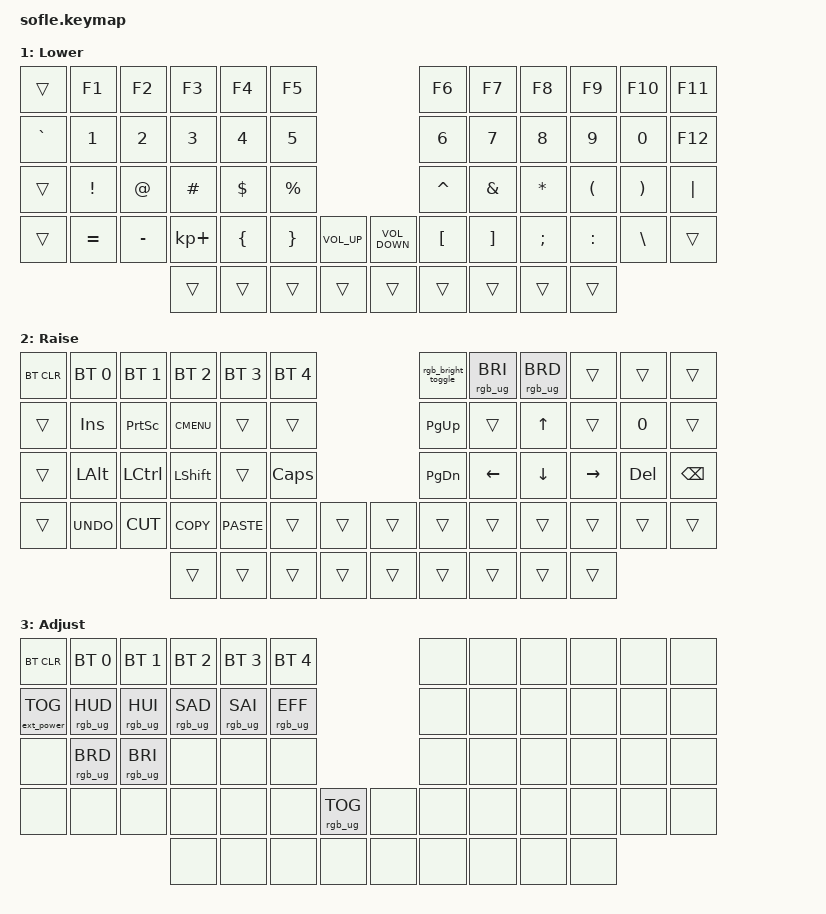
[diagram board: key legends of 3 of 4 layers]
/*
 * Copyright (c) 2020 The ZMK Contributors
 *
 * SPDX-License-Identifier: MIT
 */

#include <behaviors.dtsi>
#include <dt-bindings/zmk/bt.h>
#include <dt-bindings/zmk/ext_power.h>
#include <dt-bindings/zmk/keys.h>
#include <dt-bindings/zmk/outputs.h>
#include <dt-bindings/zmk/rgb.h>

// LED strip configuration for RGB
&led_strip {
    chain-length = <35>;
};

// Left encoder configuration
&left_encoder {
    resolution = <2>;
};

/ {
    // Activate ADJUST layer by pressing raise and lower
    conditional_layers {
        compatible = "zmk,conditional-layers";
        adjust_layer {
            if-layers = <1 2>;
            then-layer = <3>;
        };
    };

    macros {
        rgb_brightness_off: rgb_brightness_off {
            compatible = "zmk,behavior-macro";
            #binding-cells = <0>;
            bindings = <&rgb_ug RGB_BRD &rgb_ug RGB_BRD &rgb_ug RGB_BRD &rgb_ug RGB_BRD &rgb_ug RGB_BRD>;
        };
        rgb_brightness_on: rgb_brightness_on {
            compatible = "zmk,behavior-macro";
            #binding-cells = <0>;
            bindings = <&rgb_ug RGB_BRI &rgb_ug RGB_BRI &rgb_ug RGB_BRI>;
        };
    };

    behaviors {
        rgb_bright_toggle: rgb_bright_toggle {
            compatible = "zmk,behavior-mod-morph";
            label = "RGB_BRIGHT_TOGGLE";
            #binding-cells = <0>;
            bindings = <&rgb_brightness_off>, <&rgb_brightness_on>;
            mods = <(MOD_LSFT|MOD_RSFT)>;
        };
    };

    keymap {
        compatible = "zmk,keymap";

        // =================================================================
        // LAYER 0: DEFAULT (QWERTY)
        // =================================================================
        default_layer {
            label = "QWERTY";
            // ┌─────┬─────┬─────┬─────┬─────┬─────┐                    ┌─────┬─────┬─────┬─────┬─────┬─────┐
            // │  `  │  1  │  2  │  3  │  4  │  5  │                    │  6  │  7  │  8  │  9  │  0  │  -  │
            // ├─────┼─────┼─────┼─────┼─────┼─────┤                    ├─────┼─────┼─────┼─────┼─────┼─────┤
            // │ ESC │  Q  │  W  │  E  │  R  │  T  │                    │  Y  │  U  │  I  │  O  │  P  │BKSPC│
            // ├─────┼─────┼─────┼─────┼─────┼─────┤                    ├─────┼─────┼─────┼─────┼─────┼─────┤
            // │ TAB │  A  │  S  │  D  │  F  │  G  │                    │  H  │  J  │  K  │  L  │  ;  │  '  │
            // ├─────┼─────┼─────┼─────┼─────┼─────┼─────┐        ┌─────┼─────┼─────┼─────┼─────┼─────┼─────┤
            // │SHIFT│  Z  │  X  │  C  │  V  │  B  │MUTE │        │     │  N  │  M  │  ,  │  .  │  /  │SHIFT│
            // └─────┴─────┴─────┼─────┼─────┼─────┼─────┤        ├─────┼─────┼─────┼─────┴─────┴─────┴─────┘
            //                   │ GUI │ ALT │CTRL │LOWER│        │RAISE│RCTRL│RALT │  \  │
            //                   │     │     │     │     │        │     │     │     │     │
            //                   └─────┴─────┴─────┼─────┤        ├─────┼─────┴─────┴─────┘
            //                                     │SPACE│        │ RET │
            //                                     └─────┘        └─────┘
            bindings = <
                &kp GRAVE  &kp N1    &kp N2    &kp N3     &kp N4     &kp N5                           &kp N6     &kp N7     &kp N8     &kp N9    &kp N0    &kp MINUS
                &kp ESC    &kp Q     &kp W     &kp E      &kp R      &kp T                            &kp Y      &kp U      &kp I      &kp O     &kp P     &kp BSPC
                &kp TAB    &kp A     &kp S     &kp D      &kp F      &kp G                            &kp H      &kp J      &kp K      &kp L     &kp SEMI  &kp SQT
                &kp LSHFT  &kp Z     &kp X     &kp C      &kp V      &kp B  &kp C_MUTE     &kp C_MUTE &kp N      &kp M      &kp COMMA  &kp DOT   &kp SLASH &kp RSHFT
                                     &kp LGUI  &kp LALT   &kp LCTRL  &mo 1  &kp SPACE      &kp RET    &mo 2      &kp RCTRL  &kp RALT   &kp BACKSLASH
            >;

            sensor-bindings = <&inc_dec_kp C_VOL_UP C_VOL_DN &inc_dec_kp PG_UP PG_DN>;
        };

        // =================================================================
        // LAYER 1: LOWER (NUMBERS, SYMBOLS, FUNCTION KEYS)
        // =================================================================
        lower_layer {
            label = "Lower";
            // ┌─────┬─────┬─────┬─────┬─────┬─────┐                    ┌─────┬─────┬─────┬─────┬─────┬─────┐
            // │     │ F1  │ F2  │ F3  │ F4  │ F5  │                    │ F6  │ F7  │ F8  │ F9  │ F10 │ F11 │
            // ├─────┼─────┼─────┼─────┼─────┼─────┤                    ├─────┼─────┼─────┼─────┼─────┼─────┤
            // │  `  │  1  │  2  │  3  │  4  │  5  │                    │  6  │  7  │  8  │  9  │  0  │ F12 │
            // ├─────┼─────┼─────┼─────┼─────┼─────┤                    ├─────┼─────┼─────┼─────┼─────┼─────┤
            // │     │  !  │  @  │  #  │  $  │  %  │                    │  ^  │  &  │  *  │  (  │  )  │  |  │
            // ├─────┼─────┼─────┼─────┼─────┼─────┼─────┐        ┌─────┼─────┼─────┼─────┼─────┼─────┼─────┤
            // │     │  =  │  -  │  +  │  {  │  }  │VOLUP│        │VOLDW│  [  │  ]  │  ;  │  :  │  \  │     │
            // └─────┴─────┴─────┼─────┼─────┼─────┼─────┤        ├─────┼─────┼─────┼─────┴─────┴─────┴─────┘
            //                   │     │     │     │     │        │     │     │     │     │
            //                   │     │     │     │     │        │     │     │     │     │
            //                   └─────┴─────┴─────┼─────┤        ├─────┼─────┴─────┴─────┘
            //                                     │     │        │     │
            //                                     └─────┘        └─────┘
            bindings = <
                &trans     &kp F1     &kp F2     &kp F3       &kp F4     &kp F5                                           &kp F6     &kp F7    &kp F8     &kp F9     &kp F10   &kp F11
                &kp GRAVE  &kp N1     &kp N2     &kp N3       &kp N4     &kp N5                                           &kp N6     &kp N7    &kp N8     &kp N9     &kp N0    &kp F12
                &trans     &kp EXCL   &kp AT     &kp HASH     &kp DLLR   &kp PRCNT                                        &kp CARET  &kp AMPS  &kp ASTRK  &kp LPAR   &kp RPAR  &kp PIPE
                &trans     &kp EQUAL  &kp MINUS  &kp KP_PLUS  &kp LBRC   &kp RBRC   &kp C_VOLUME_UP    &kp C_VOLUME_DOWN  &kp LBKT   &kp RBKT  &kp SEMI   &kp COLON  &kp BSLH  &trans
                                                 &trans       &trans     &trans     &trans             &trans  &trans     &trans     &trans    &trans
            >;

            sensor-bindings = <&inc_dec_kp C_VOL_UP C_VOL_DN &inc_dec_kp PG_UP PG_DN>;
        };

        // =================================================================
        // LAYER 2: RAISE (NAVIGATION, BLUETOOTH, SYSTEM)
        // =================================================================
        raise_layer {
            label = "Raise";
            // ┌─────┬─────┬─────┬─────┬─────┬─────┐                    ┌─────┬─────┬─────┬─────┬─────┬─────┐
            // │BTCLR│ BT1 │ BT2 │ BT3 │ BT4 │ BT5 │                    │RGB↕ │RGB+ │RGB- │     │     │     │
            // ├─────┼─────┼─────┼─────┼─────┼─────┤                    ├─────┼─────┼─────┼─────┼─────┼─────┤
            // │     │ INS │PSCR │MENU │     │     │                    │PGUP │     │  ↑  │     │  0  │     │
            // ├─────┼─────┼─────┼─────┼─────┼─────┤                    ├─────┼─────┼─────┼─────┼─────┼─────┤
            // │     │ ALT │CTRL │SHIFT│     │CAPS │                    │PGDN │  ←  │  ↓  │  →  │ DEL │BKSPC│
            // ├─────┼─────┼─────┼─────┼─────┼─────┼─────┐        ┌─────┼─────┼─────┼─────┼─────┼─────┼─────┤
            // │     │UNDO │ CUT │COPY │PASTE│     │     │        │     │     │     │     │     │     │     │
            // └─────┴─────┴─────┼─────┼─────┼─────┼─────┤        ├─────┼─────┼─────┼─────┴─────┴─────┴─────┘
            //                   │     │     │     │     │        │     │     │     │     │
            //                   │     │     │     │     │        │     │     │     │     │
            //                   └─────┴─────┴─────┼─────┤        ├─────┼─────┴─────┴─────┘
            //                                     │     │        │     │
            //                                     └─────┘        └─────┘
            bindings = <
                &bt BT_CLR  &bt BT_SEL 0  &bt BT_SEL 1  &bt BT_SEL 2  &bt BT_SEL 3  &bt BT_SEL 4                          &rgb_bright_toggle  &rgb_ug RGB_BRI  &rgb_ug RGB_BRD  &trans     &trans  &trans
                &trans      &kp INS       &kp PSCRN     &kp K_CMENU   &trans        &trans                                &kp PG_UP        &trans           &kp UP           &trans     &kp N0  &trans
                &trans      &kp LALT      &kp LCTRL     &kp LSHFT     &trans        &kp CLCK                              &kp PG_DN        &kp LEFT         &kp DOWN         &kp RIGHT  &kp DEL &kp BSPC
                &trans      &kp K_UNDO    &kp K_CUT     &kp K_COPY    &kp K_PASTE   &trans       &trans     &trans        &trans           &trans           &trans           &trans     &trans  &trans
                                                        &trans        &trans        &trans       &trans     &trans        &trans           &trans           &trans           &trans
            >;

            sensor-bindings = <&inc_dec_kp C_VOL_UP C_VOL_DN &inc_dec_kp PG_UP PG_DN>;
        };

        // =================================================================
        // LAYER 3: ADJUST (RGB CONTROLS, ADVANCED BLUETOOTH, SYSTEM)
        // =================================================================
        adjust_layer {
            label = "Adjust";
            // ┌─────┬─────┬─────┬─────┬─────┬─────┐                    ┌─────┬─────┬─────┬─────┬─────┬─────┐
            // │BTCLR│ BT1 │ BT2 │ BT3 │ BT4 │ BT5 │                    │     │     │     │     │     │     │
            // ├─────┼─────┼─────┼─────┼─────┼─────┤                    ├─────┼─────┼─────┼─────┼─────┼─────┤
            // │EXTPW│RGB_H│RGB_H│RGB_S│RGB_S│RGB_E│                    │     │     │     │     │     │     │
            // │ TOG │ DWN │ UP  │ DWN │ UP  │ FF  │                    │     │     │     │     │     │     │
            // ├─────┼─────┼─────┼─────┼─────┼─────┤                    ├─────┼─────┼─────┼─────┼─────┼─────┤
            // │     │RGB_B│RGB_B│     │     │     │                    │     │     │     │     │     │     │
            // │     │ DWN │ UP  │     │     │     │                    │     │     │     │     │     │     │
            // ├─────┼─────┼─────┼─────┼─────┼─────┼─────┐        ┌─────┼─────┼─────┼─────┼─────┼─────┼─────┤
            // │     │     │     │     │     │     │RGB_T│        │     │     │     │     │     │     │     │
            // │     │     │     │     │     │     │ OG  │        │     │     │     │     │     │     │     │
            // └─────┴─────┴─────┼─────┼─────┼─────┼─────┤        ├─────┼─────┼─────┼─────┴─────┴─────┴─────┘
            //                   │     │     │     │     │        │     │     │     │     │
            //                   │     │     │     │     │        │     │     │     │     │
            //                   └─────┴─────┴─────┼─────┤        ├─────┼─────┴─────┴─────┘
            //                                     │     │        │     │
            //                                     └─────┘        └─────┘
            bindings = <
                &bt BT_CLR        &bt BT_SEL 0      &bt BT_SEL 1      &bt BT_SEL 2      &bt BT_SEL 3      &bt BT_SEL 4                        &none  &none  &none  &none  &none  &none
                &ext_power EP_TOG &rgb_ug RGB_HUD   &rgb_ug RGB_HUI   &rgb_ug RGB_SAD   &rgb_ug RGB_SAI   &rgb_ug RGB_EFF                     &none  &none  &none  &none  &none  &none
                &none             &rgb_ug RGB_BRD   &rgb_ug RGB_BRI   &none             &none             &none                               &none  &none  &none  &none  &none  &none
                &none             &none             &none             &none             &none             &none             &rgb_ug RGB_TOG   &none  &none  &none  &none  &none  &none  &none
                                                                      &none             &none             &none             &none             &none  &none  &none  &none  &none
            >;

            sensor-bindings = <&inc_dec_kp C_VOL_UP C_VOL_DN &inc_dec_kp PG_UP PG_DN>;
        };
    };
};
